VERSION "HIPBNYYYYYYYYYYYYYYYYYYYYYYYYYYYYYYYYYYYYY/4/%%%/4/'%**4YYY///"

NS_ :

BS_:

BU_:

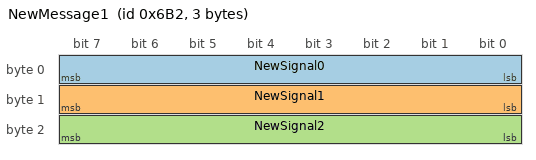
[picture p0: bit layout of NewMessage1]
BO_ 1714 NewMessage1: 3 Vector__XXX
 SG_ NewSignal0 : 7|8@0+ (1,0) [0|0] "" Vector__XXX
 SG_ NewSignal1 : 15|8@0+ (0.1,0) [0|0] "" Vector__XXX
 SG_ NewSignal2 : 23|8@0+ (0.1,0) [0|0] "" Vector__XXX
